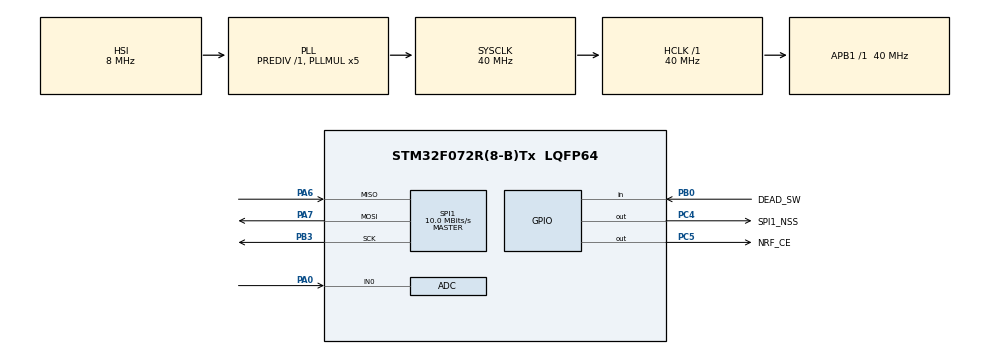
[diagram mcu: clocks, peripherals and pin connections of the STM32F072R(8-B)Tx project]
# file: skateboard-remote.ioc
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ADC.ClockPrescaler=ADC_CLOCK_ASYNC_DIV1
ADC.LowPowerAutoWait=ENABLE
ADC.Resolution=ADC_RESOLUTION_6B
Mcu.Family=STM32F0
Mcu.Name=STM32F072R(8-B)Tx
Mcu.Package=LQFP64
PA0.Mode=IN0
PA0.Signal=ADC_IN0
PA13.GPIO_Label=TMS
PA13.Mode=Serial_Wire
PA13.Signal=SYS_SWDIO
PA14.GPIO_Label=TCK
PA14.Mode=Serial_Wire
PA14.Signal=SYS_SWCLK
PA6.Mode=Full_Duplex_Master
PA6.Signal=SPI1_MISO
PA7.Mode=Full_Duplex_Master
PA7.Signal=SPI1_MOSI
PB0.GPIO_Label=DEAD_SW
PB0.GPIO_PuPd=GPIO_PULLUP
PB0.Signal=GPIO_Input
PB3.Mode=Full_Duplex_Master
PB3.Signal=SPI1_SCK
PC14-OSC32_IN.Mode=LSE-External-Oscillator
PC14-OSC32_IN.Signal=RCC_OSC32_IN
PC15-OSC32_OUT.Mode=LSE-External-Oscillator
PC15-OSC32_OUT.Signal=RCC_OSC32_OUT
PC4.GPIO_Label=SPI1_NSS
PC4.PinState=GPIO_PIN_SET
PC4.Signal=GPIO_Output
PC5.GPIO_Label=NRF_CE
PC5.Signal=GPIO_Output
PF0-OSC_IN.Mode=HSE-External-Clock-Source
PF0-OSC_IN.Signal=RCC_OSC_IN
PF1-OSC_OUT.Signal=RCC_OSC_OUT
ProjectManager.HeapSize=0x200
ProjectManager.StackSize=0x400
ProjectManager.TargetToolchain=STM32CubeIDE
RCC.AHBFreq_Value=40000000
RCC.APB1Freq_Value=40000000
RCC.APB1TimFreq_Value=40000000
RCC.FLatency-AdvancedSettings=FLASH_LATENCY_1
RCC.HCLKFreq_Value=40000000
RCC.PLLMUL=RCC_PLL_MUL5
RCC.PREFETCH_ENABLE-AdvancedSettings=1
RCC.SYSCLKFreq_VALUE=40000000
RCC.SYSCLKSource=RCC_SYSCLKSOURCE_PLLCLK
SPI1.BaudRatePrescaler=SPI_BAUDRATEPRESCALER_4
SPI1.CalculateBaudRate=10.0 MBits/s
SPI1.DataSize=SPI_DATASIZE_8BIT
SPI1.Direction=SPI_DIRECTION_2LINES
SPI1.Mode=SPI_MODE_MASTER
SPI1.NSSPMode=SPI_NSS_PULSE_DISABLE
SPI1.VirtualType=VM_MASTER
board=NUCLEO-F072RB

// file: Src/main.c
/* USER CODE BEGIN Header */
/**
  ******************************************************************************
  * @file           : main.c
  * @brief          : Main program body
  ******************************************************************************
  * @attention
  *
  * <h2><center>&copy; Copyright (c) 2020 STMicroelectronics.
  * All rights reserved.</center></h2>
  *
  * This software component is licensed by ST under BSD 3-Clause license,
  * the "License"; You may not use this file except in compliance with the
  * License. You may obtain a copy of the License at:
  *                        opensource.org/licenses/BSD-3-Clause
  *
  ******************************************************************************
  */
/* USER CODE END Header */

#include "main.h"

ADC_HandleTypeDef hadc;

SPI_HandleTypeDef hspi1;

void SystemClock_Config(void);
static void MX_GPIO_Init(void);
static void MX_ADC_Init(void);
static void MX_SPI1_Init(void);

int main(void)
{

  /* MCU Configuration--------------------------------------------------------*/

  /* Reset of all peripherals, Initializes the Flash interface and the Systick. */
  HAL_Init();

  /* Configure the system clock */
  SystemClock_Config();

  /* Initialize all configured peripherals */
  MX_GPIO_Init();
  MX_ADC_Init();
  MX_SPI1_Init();
  /* USER CODE BEGIN 2 */
  // setup the WiFi module

  /* USER CODE END 2 */

  /* Infinite loop */
  /* USER CODE BEGIN WHILE */
  uint8_t testData = 0xA6;
  HAL_GPIO_WritePin(NRF_CE_GPIO_Port, NRF_CE_Pin, GPIO_PIN_SET);
  while (1)
  {
	  HAL_GPIO_WritePin(NRF_CE_GPIO_Port, NRF_CE_Pin, GPIO_PIN_RESET);
	  HAL_SPI_Transmit(&hspi1, &testData, 1, HAL_MAX_DELAY);
	  HAL_GPIO_WritePin(NRF_CE_GPIO_Port, NRF_CE_Pin, GPIO_PIN_SET);
	  HAL_Delay(500);
    /* USER CODE END WHILE */

  }
}

void SystemClock_Config(void)
{
  RCC_OscInitTypeDef RCC_OscInitStruct = {0};
  RCC_ClkInitTypeDef RCC_ClkInitStruct = {0};

  /** Initializes the CPU, AHB and APB busses clocks
  */
  RCC_OscInitStruct.OscillatorType = RCC_OSCILLATORTYPE_HSI|RCC_OSCILLATORTYPE_HSI14;
  RCC_OscInitStruct.HSIState = RCC_HSI_ON;
  RCC_OscInitStruct.HSI14State = RCC_HSI14_ON;
  RCC_OscInitStruct.HSICalibrationValue = RCC_HSICALIBRATION_DEFAULT;
  RCC_OscInitStruct.HSI14CalibrationValue = 16;
  RCC_OscInitStruct.PLL.PLLState = RCC_PLL_ON;
  RCC_OscInitStruct.PLL.PLLSource = RCC_PLLSOURCE_HSI;
  RCC_OscInitStruct.PLL.PLLMUL = RCC_PLL_MUL5;
  RCC_OscInitStruct.PLL.PREDIV = RCC_PREDIV_DIV1;
  if (HAL_RCC_OscConfig(&RCC_OscInitStruct) != HAL_OK)
  {
    Error_Handler();
  }
  /** Initializes the CPU, AHB and APB busses clocks
  */
  RCC_ClkInitStruct.ClockType = RCC_CLOCKTYPE_HCLK|RCC_CLOCKTYPE_SYSCLK
                              |RCC_CLOCKTYPE_PCLK1;
  RCC_ClkInitStruct.SYSCLKSource = RCC_SYSCLKSOURCE_PLLCLK;
  RCC_ClkInitStruct.AHBCLKDivider = RCC_SYSCLK_DIV1;
  RCC_ClkInitStruct.APB1CLKDivider = RCC_HCLK_DIV1;

  if (HAL_RCC_ClockConfig(&RCC_ClkInitStruct, FLASH_LATENCY_1) != HAL_OK)
  {
    Error_Handler();
  }
}

static void MX_ADC_Init(void)
{

  ADC_ChannelConfTypeDef sConfig = {0};

  /** Configure the global features of the ADC (Clock, Resolution, Data Alignment and number of conversion)
  */
  hadc.Instance = ADC1;
  hadc.Init.ClockPrescaler = ADC_CLOCK_ASYNC_DIV1;
  hadc.Init.Resolution = ADC_RESOLUTION_6B;
  hadc.Init.DataAlign = ADC_DATAALIGN_RIGHT;
  hadc.Init.ScanConvMode = ADC_SCAN_DIRECTION_FORWARD;
  hadc.Init.EOCSelection = ADC_EOC_SINGLE_CONV;
  hadc.Init.LowPowerAutoWait = ENABLE;
  hadc.Init.LowPowerAutoPowerOff = DISABLE;
  hadc.Init.ContinuousConvMode = DISABLE;
  hadc.Init.DiscontinuousConvMode = DISABLE;
  hadc.Init.ExternalTrigConv = ADC_SOFTWARE_START;
  hadc.Init.ExternalTrigConvEdge = ADC_EXTERNALTRIGCONVEDGE_NONE;
  hadc.Init.DMAContinuousRequests = DISABLE;
  hadc.Init.Overrun = ADC_OVR_DATA_PRESERVED;
  if (HAL_ADC_Init(&hadc) != HAL_OK)
  {
    Error_Handler();
  }
  /** Configure for the selected ADC regular channel to be converted.
  */
  sConfig.Channel = ADC_CHANNEL_0;
  sConfig.Rank = ADC_RANK_CHANNEL_NUMBER;
  sConfig.SamplingTime = ADC_SAMPLETIME_1CYCLE_5;
  if (HAL_ADC_ConfigChannel(&hadc, &sConfig) != HAL_OK)
  {
    Error_Handler();
  }

}

static void MX_SPI1_Init(void)
{

  /* SPI1 parameter configuration*/
  hspi1.Instance = SPI1;
  hspi1.Init.Mode = SPI_MODE_MASTER;
  hspi1.Init.Direction = SPI_DIRECTION_2LINES;
  hspi1.Init.DataSize = SPI_DATASIZE_8BIT;
  hspi1.Init.CLKPolarity = SPI_POLARITY_LOW;
  hspi1.Init.CLKPhase = SPI_PHASE_1EDGE;
  hspi1.Init.NSS = SPI_NSS_SOFT;
  hspi1.Init.BaudRatePrescaler = SPI_BAUDRATEPRESCALER_4;
  hspi1.Init.FirstBit = SPI_FIRSTBIT_MSB;
  hspi1.Init.TIMode = SPI_TIMODE_DISABLE;
  hspi1.Init.CRCCalculation = SPI_CRCCALCULATION_DISABLE;
  hspi1.Init.CRCPolynomial = 7;
  hspi1.Init.CRCLength = SPI_CRC_LENGTH_DATASIZE;
  hspi1.Init.NSSPMode = SPI_NSS_PULSE_DISABLE;
  if (HAL_SPI_Init(&hspi1) != HAL_OK)
  {
    Error_Handler();
  }

}

static void MX_GPIO_Init(void)
{
  GPIO_InitTypeDef GPIO_InitStruct = {0};

  /* GPIO Ports Clock Enable */
  __HAL_RCC_GPIOC_CLK_ENABLE();
  __HAL_RCC_GPIOF_CLK_ENABLE();
  __HAL_RCC_GPIOA_CLK_ENABLE();
  __HAL_RCC_GPIOB_CLK_ENABLE();

  /*Configure GPIO pin Output Level */
  HAL_GPIO_WritePin(SPI1_NSS_GPIO_Port, SPI1_NSS_Pin, GPIO_PIN_SET);

  /*Configure GPIO pin Output Level */
  HAL_GPIO_WritePin(NRF_CE_GPIO_Port, NRF_CE_Pin, GPIO_PIN_RESET);

  /*Configure GPIO pins : SPI1_NSS_Pin NRF_CE_Pin */
  GPIO_InitStruct.Pin = SPI1_NSS_Pin|NRF_CE_Pin;
  GPIO_InitStruct.Mode = GPIO_MODE_OUTPUT_PP;
  GPIO_InitStruct.Pull = GPIO_NOPULL;
  GPIO_InitStruct.Speed = GPIO_SPEED_FREQ_LOW;
  HAL_GPIO_Init(GPIOC, &GPIO_InitStruct);

  /*Configure GPIO pin : DEAD_SW_Pin */
  GPIO_InitStruct.Pin = DEAD_SW_Pin;
  GPIO_InitStruct.Mode = GPIO_MODE_INPUT;
  GPIO_InitStruct.Pull = GPIO_PULLUP;
  HAL_GPIO_Init(DEAD_SW_GPIO_Port, &GPIO_InitStruct);

}

void Error_Handler(void)
{
}

/************************ (C) COPYRIGHT STMicroelectronics *****END OF FILE****/
